# ESP32-S2 register map
Vendor: ESPRESSIF SYSTEMS (SHANGHAI) CO., LTD.; Series: ESP32 S-Series; File version: 20
CPU: Xtensa LX7 r0p0, little endian, no MPU, no FPU, 0 interrupt priority bits
Address unit: 32 bits
Registers are 32-bit, read-write, reset 0x0 unless marked. A register's access mark holds for its fields unless they carry their own. Offsets are from the block's base; [hi:lo] are bit positions; {n}, {i} and the like mark numbered series; 'fields as' and 'values as' point back to an identical list.

## IO_MUX — Input/Output Multiplexer
Base 0x3F409000
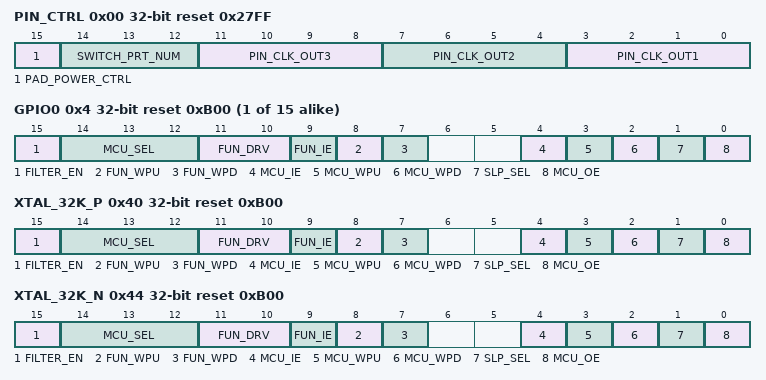
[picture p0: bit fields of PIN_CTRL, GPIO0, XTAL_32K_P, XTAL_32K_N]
0x00 PIN_CTRL reset 0x27FF — Clock output configuration register
  [15] PAD_POWER_CTRL — Select power voltage for GPIO33 ~ GPIO37. 1: select VDD_SPI 1.8 V. 0: select VDD3P3_CPU 3.3 V.
  [14:12] SWITCH_PRT_NUM — IO pin power switch delay, delay unit is one APB clock.
  [11:8] PIN_CLK_OUT3 — Configure I2S0 clock output. 0: output I2S0 clock to CLK_OUT3. 15: disabled.
  [7:4] PIN_CLK_OUT2 — Configure I2S0 clock output. 0: output I2S0 clock to CLK_OUT2. 15: disabled.
  [3:0] PIN_CLK_OUT1 — Configure I2S0 clock output. 0: output I2S0 clock to CLK_OUT1. 15: disabled.
{0x4+4i} GPIO{i} reset 0xB00 (i=0..14) — Configuration register for pin GPIO{i}
  [15] FILTER_EN — Enable filter for pin input signals. 1: Filter enabled. 2: Filter disabled.
  [14:12] MCU_SEL — Select IO MUX function for this signal. 0: Select Function 1. 1: Select Function 2, etc.
  [11:10] FUN_DRV — Select the drive strength of the pin. 0: ~5 mA. 1: ~10 mA. 2: ~20 mA. 3: ~40 mA.
  [9] FUN_IE — Input enable of the pin. 1: Input enabled. 0: Input disabled.
  [8] FUN_WPU — Pull-up enable of the pin. 1: Internal pull-up enabled. 0: Internal pull-up disabled.
  [7] FUN_WPD — Pull-down enable of the pin. 1: Internal pull-down enabled. 0: internal pull-down disabled.
  [4] MCU_IE — Input enable of the pin during sleep mode. 1: Input enabled. 0: Input disabled.
  [3] MCU_WPU — Pull-up enable of the pin during sleep mode. 1: Internal pull-up enabled. 0: Internal pull-up disabled.
  [2] MCU_WPD — Pull-down enable of the pin during sleep mode. 1: Internal pull-down enabled. 0: internal pull-down disabled.
  [1] SLP_SEL — Sleep mode selection of this pin. Set to 1 to put the pin in sleep mode.
  [0] MCU_OE — Output enable of the pin in sleep mode. 1: Output enabled. 0: Output disabled.
0x40 XTAL_32K_P reset 0xB00 — Configuration register for pin XTAL_32K_P
  fields as GPIO0
0x44 XTAL_32K_N reset 0xB00 — Configuration register for pin XTAL_32K_N
  fields as GPIO0
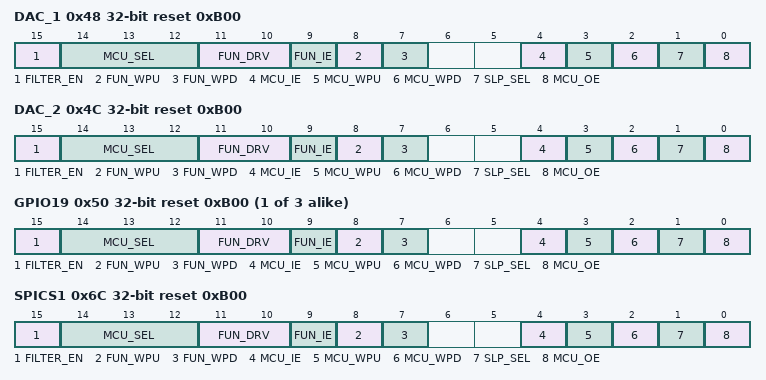
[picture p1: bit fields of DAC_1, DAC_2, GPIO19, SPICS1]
0x48 DAC_1 reset 0xB00 — Configuration register for pin DAC_1
  fields as GPIO0
0x4C DAC_2 reset 0xB00 — Configuration register for pin DAC_2
  fields as GPIO0
{0x4+4i} GPIO{i} reset 0xB00 (i=19..21) — Configuration register for pin GPIO{i}
  fields as GPIO0
0x6C SPICS1 reset 0xB00 — Configuration register for pin SPICS1
  fields as GPIO0
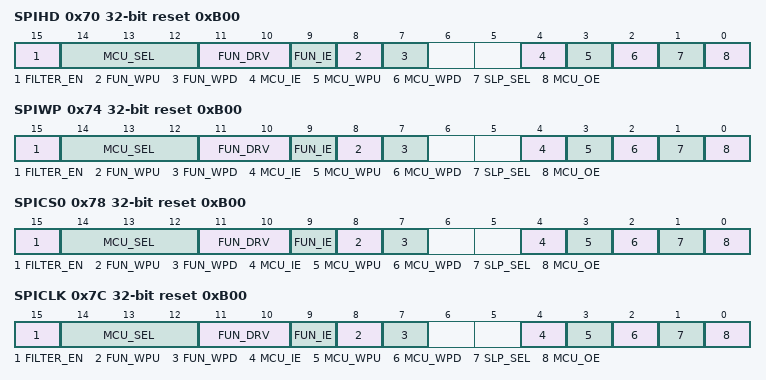
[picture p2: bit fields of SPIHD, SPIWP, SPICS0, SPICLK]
0x70 SPIHD reset 0xB00 — Configuration register for pin SPIHD
  fields as GPIO0
0x74 SPIWP reset 0xB00 — Configuration register for pin SPIWP
  fields as GPIO0
0x78 SPICS0 reset 0xB00 — Configuration register for pin SPICS0
  fields as GPIO0
0x7C SPICLK reset 0xB00 — Configuration register for pin SPICLK
  fields as GPIO0
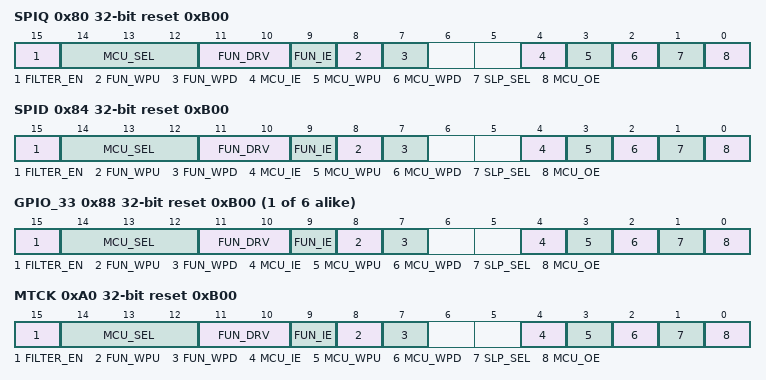
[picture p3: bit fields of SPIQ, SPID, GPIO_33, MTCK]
0x80 SPIQ reset 0xB00 — Configuration register for pin SPIQ
  fields as GPIO0
0x84 SPID reset 0xB00 — Configuration register for pin SPID
  fields as GPIO0
{0x4+4i} GPIO_{i} reset 0xB00 (i=33..38) — Configuration register for pin GPIO{i}
  fields as GPIO0
0xA0 MTCK reset 0xB00 — Configuration register for pin MTCK
  fields as GPIO0
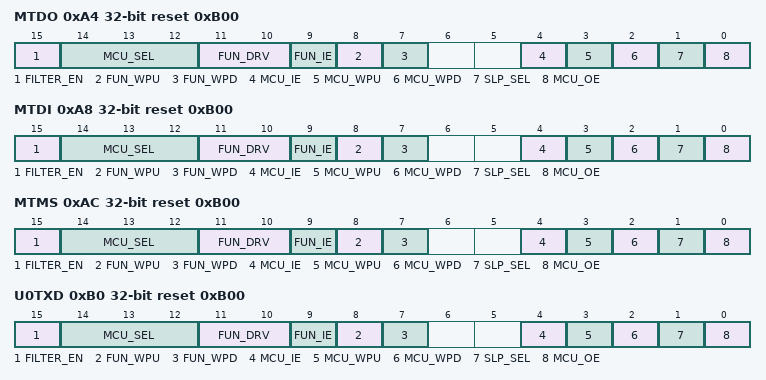
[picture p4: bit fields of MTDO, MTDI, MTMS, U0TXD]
0xA4 MTDO reset 0xB00 — Configuration register for pin MTDO
  fields as GPIO0
0xA8 MTDI reset 0xB00 — Configuration register for pin MTDI
  fields as GPIO0
0xAC MTMS reset 0xB00 — Configuration register for pin MTMS
  fields as GPIO0
0xB0 U0TXD reset 0xB00 — Configuration register for pin U0TXD
  fields as GPIO0
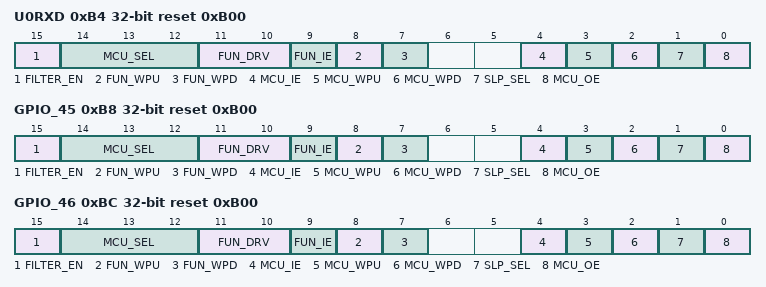
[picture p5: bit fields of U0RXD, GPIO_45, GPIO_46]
0xB4 U0RXD reset 0xB00 — Configuration register for pin U0RXD
  fields as GPIO0
0xB8 GPIO_45 reset 0xB00 — Configuration register for pin GPIO45
  fields as GPIO0
0xBC GPIO_46 reset 0xB00 — Configuration register for pin GPIO46
  fields as GPIO0
0xFC DATE reset 0x1907160 — Version control register
  [27:0] VERSION
